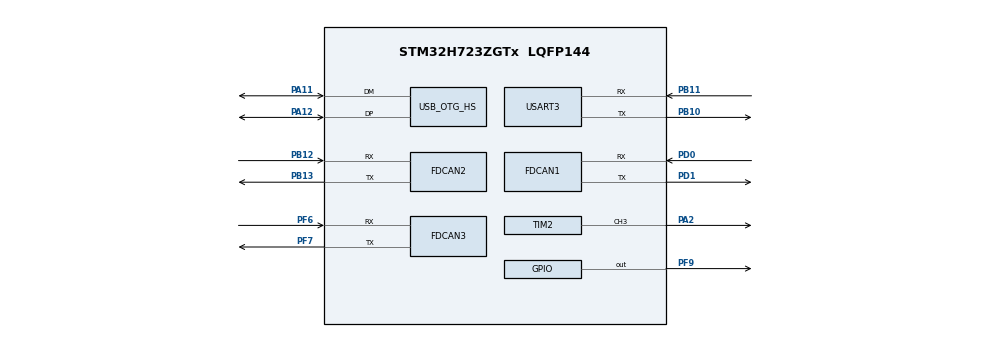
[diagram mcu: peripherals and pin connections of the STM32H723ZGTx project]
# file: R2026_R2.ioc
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CORTEX_M7.default_mode_Activation=1
Dma.Request0=USART3_RX
Dma.Request1=USART3_TX
Dma.USART3_RX.0.Direction=DMA_PERIPH_TO_MEMORY
Dma.USART3_RX.0.EventEnable=DISABLE
Dma.USART3_RX.0.FIFOMode=DMA_FIFOMODE_DISABLE
Dma.USART3_RX.0.Instance=DMA1_Stream0
Dma.USART3_RX.0.MemDataAlignment=DMA_MDATAALIGN_BYTE
Dma.USART3_RX.0.MemInc=DMA_MINC_ENABLE
Dma.USART3_RX.0.Mode=DMA_CIRCULAR
Dma.USART3_RX.0.PeriphDataAlignment=DMA_PDATAALIGN_BYTE
Dma.USART3_RX.0.PeriphInc=DMA_PINC_DISABLE
Dma.USART3_RX.0.Polarity=HAL_DMAMUX_REQ_GEN_RISING
Dma.USART3_RX.0.Priority=DMA_PRIORITY_LOW
Dma.USART3_RX.0.RequestNumber=1
Dma.USART3_RX.0.SignalID=NONE
Dma.USART3_RX.0.SyncEnable=DISABLE
Dma.USART3_RX.0.SyncPolarity=HAL_DMAMUX_SYNC_NO_EVENT
Dma.USART3_RX.0.SyncRequestNumber=1
Dma.USART3_RX.0.SyncSignalID=NONE
Dma.USART3_TX.1.Direction=DMA_MEMORY_TO_PERIPH
Dma.USART3_TX.1.EventEnable=DISABLE
Dma.USART3_TX.1.FIFOMode=DMA_FIFOMODE_DISABLE
Dma.USART3_TX.1.Instance=DMA1_Stream1
Dma.USART3_TX.1.MemDataAlignment=DMA_MDATAALIGN_BYTE
Dma.USART3_TX.1.MemInc=DMA_MINC_ENABLE
Dma.USART3_TX.1.Mode=DMA_NORMAL
Dma.USART3_TX.1.PeriphDataAlignment=DMA_PDATAALIGN_BYTE
Dma.USART3_TX.1.PeriphInc=DMA_PINC_DISABLE
Dma.USART3_TX.1.Polarity=HAL_DMAMUX_REQ_GEN_RISING
Dma.USART3_TX.1.Priority=DMA_PRIORITY_LOW
Dma.USART3_TX.1.RequestNumber=1
Dma.USART3_TX.1.SignalID=NONE
Dma.USART3_TX.1.SyncEnable=DISABLE
Dma.USART3_TX.1.SyncPolarity=HAL_DMAMUX_SYNC_NO_EVENT
Dma.USART3_TX.1.SyncRequestNumber=1
Dma.USART3_TX.1.SyncSignalID=NONE
FDCAN1.CalculateBaudRateNominal=1000000
FDCAN1.CalculateTimeBitNominal=1000
FDCAN1.CalculateTimeQuantumNominal=40.0
FDCAN1.DataSyncJumpWidth=2
FDCAN1.DataTimeSeg1=15
FDCAN1.DataTimeSeg2=9
FDCAN1.ExtFiltersNbr=2
FDCAN1.NominalPrescaler=1
FDCAN1.NominalSyncJumpWidth=2
FDCAN1.NominalTimeSeg1=15
FDCAN1.NominalTimeSeg2=9
FDCAN1.RxFifo0ElmtsNbr=8
FDCAN1.RxFifo1ElmtsNbr=8
FDCAN1.StdFiltersNbr=2
FDCAN1.TxBuffersNbr=29
FDCAN1.TxFifoQueueElmtsNbr=3
FDCAN2.CalculateBaudRateNominal=1000000
FDCAN2.CalculateTimeBitNominal=1000
FDCAN2.CalculateTimeQuantumNominal=40.0
FDCAN2.DataSyncJumpWidth=2
FDCAN2.DataTimeSeg1=15
FDCAN2.DataTimeSeg2=9
FDCAN2.ExtFiltersNbr=2
FDCAN2.MessageRAMOffset=0x400
FDCAN2.NominalPrescaler=1
FDCAN2.NominalSyncJumpWidth=2
FDCAN2.NominalTimeSeg1=15
FDCAN2.NominalTimeSeg2=9
FDCAN2.RxFifo0ElmtsNbr=8
FDCAN2.RxFifo1ElmtsNbr=8
FDCAN2.StdFiltersNbr=2
FDCAN2.TxBuffersNbr=29
FDCAN2.TxFifoQueueElmtsNbr=3
FDCAN3.CalculateBaudRateNominal=1000000
FDCAN3.CalculateTimeBitNominal=1000
FDCAN3.CalculateTimeQuantumNominal=40.0
FDCAN3.DataSyncJumpWidth=2
FDCAN3.DataTimeSeg1=15
FDCAN3.DataTimeSeg2=9
FDCAN3.ExtFiltersNbr=2
FDCAN3.MessageRAMOffset=0x800
FDCAN3.NominalPrescaler=1
FDCAN3.NominalSyncJumpWidth=2
FDCAN3.NominalTimeSeg1=15
FDCAN3.NominalTimeSeg2=9
FDCAN3.RxFifo0ElmtsNbr=8
FDCAN3.RxFifo1ElmtsNbr=8
FDCAN3.StdFiltersNbr=2
FDCAN3.TxBuffersNbr=29
FDCAN3.TxFifoQueueElmtsNbr=3
FREERTOS.Tasks01=defaultTask,24,128,StartDefaultTask,Default,NULL,Dynamic,NULL,NULL
FREERTOS.configENABLE_FPU=1
Mcu.Family=STM32H7
Mcu.Name=STM32H723ZGTx
Mcu.Package=LQFP144
NVIC.DMA1_Stream0_IRQn=true\:5\:0\:false\:false\:true\:true\:false\:true\:true
NVIC.DMA1_Stream1_IRQn=true\:5\:0\:false\:false\:true\:true\:false\:true\:true
NVIC.FDCAN1_IT0_IRQn=true\:5\:0\:false\:false\:true\:true\:true\:true\:true
NVIC.FDCAN1_IT1_IRQn=true\:5\:0\:false\:false\:true\:true\:true\:true\:true
NVIC.FDCAN2_IT0_IRQn=true\:5\:0\:false\:false\:true\:true\:true\:true\:true
NVIC.FDCAN2_IT1_IRQn=true\:5\:0\:false\:false\:true\:true\:true\:true\:true
NVIC.FDCAN3_IT0_IRQn=true\:5\:0\:false\:false\:true\:true\:true\:true\:true
NVIC.FDCAN3_IT1_IRQn=true\:5\:0\:false\:false\:true\:true\:true\:true\:true
NVIC.OTG_HS_IRQn=true\:5\:0\:false\:false\:true\:true\:false\:true\:true
NVIC.PriorityGroup=NVIC_PRIORITYGROUP_4
NVIC.TIM6_DAC_IRQn=true\:15\:0\:false\:false\:true\:false\:false\:true\:true
NVIC.TimeBase=TIM6_DAC_IRQn
NVIC.TimeBaseIP=TIM6
NVIC.USART3_IRQn=true\:5\:0\:false\:false\:true\:true\:true\:true\:true
PA11.Mode=Device_Only_FS
PA11.Signal=USB_OTG_HS_DM
PA12.Mode=Device_Only_FS
PA12.Signal=USB_OTG_HS_DP
PA2.Signal=S_TIM2_CH3
PB10.Mode=Asynchronous
PB10.Signal=USART3_TX
PB11.Mode=Asynchronous
PB11.Signal=USART3_RX
PB12.Mode=FDCAN_Activate
PB12.Signal=FDCAN2_RX
PB13.Mode=FDCAN_Activate
PB13.Signal=FDCAN2_TX
PD0.Mode=FDCAN_Activate
PD0.Signal=FDCAN1_RX
PD1.Mode=FDCAN_Activate
PD1.Signal=FDCAN1_TX
PF6.Mode=FDCAN_Activate
PF6.Signal=FDCAN3_RX
PF7.Mode=FDCAN_Activate
PF7.Signal=FDCAN3_TX
PF9.Signal=GPIO_Output
PH0-OSC_IN.Mode=HSE-External-Oscillator
PH0-OSC_IN.Signal=RCC_OSC_IN
PH1-OSC_OUT.Mode=HSE-External-Oscillator
PH1-OSC_OUT.Signal=RCC_OSC_OUT
ProjectManager.HeapSize=0x200
ProjectManager.StackSize=0x400
ProjectManager.TargetToolchain=CMake
RCC.ADCFreq_Value=50390625
RCC.APB1Freq_Value=137500000
RCC.APB2Freq_Value=137500000
RCC.APB3Freq_Value=137500000
RCC.APB4Freq_Value=137500000
RCC.CortexFreq_Value=275000000
RCC.D1PPRE=RCC_APB3_DIV2
RCC.D2PPRE1=RCC_APB1_DIV2
RCC.D2PPRE2=RCC_APB2_DIV2
RCC.D3PPRE=RCC_APB4_DIV2
RCC.DIVM1=2
RCC.DIVN1=22
RCC.DIVP1=1
RCC.FDCANCLockSelection=RCC_FDCANCLKSOURCE_HSE
RCC.HCLKFreq_Value=275000000
RCC.PLL2FRACN=0
RCC.PLL3FRACN=0
RCC.PLLFRACN=0
RCC.PLLSourceVirtual=RCC_PLLSOURCE_HSE
RCC.SYSCLKFreq_VALUE=275000000
RCC.SYSCLKSource=RCC_SYSCLKSOURCE_PLLCLK
RCC.USBCLockSelection=RCC_USBCLKSOURCE_HSI48
RCC.USBFreq_Value=48000000
SH.S_TIM2_CH3.0=TIM2_CH3,PWM Generation3 CH3
TIM2.Channel-PWM\ Generation3\ CH3=TIM_CHANNEL_3
TIM2.Period=100-1
USART3.VirtualMode-Asynchronous=VM_ASYNC
USB_DEVICE.CLASS_NAME_HS=CDC
USB_DEVICE.VirtualMode=Cdc
USB_DEVICE.VirtualModeHS=Cdc_HS
USB_OTG_HS.VirtualMode-Device_Only_FS=Device_Only_FS
VP_FREERTOS_VS_CMSIS_V2.Mode=CMSIS_V2
VP_MEMORYMAP_VS_MEMORYMAP.Mode=CurAppReg
VP_SYS_VS_tim6.Mode=TIM6
VP_USB_DEVICE_VS_USB_DEVICE_CDC_HS.Mode=CDC_HS
board=custom

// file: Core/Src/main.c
/* USER CODE BEGIN Header */
/**
 ******************************************************************************
 * @file           : main.c
 * @brief          : Main program body
 ******************************************************************************
 * @attention
 *
 * Copyright (c) 2026 STMicroelectronics.
 * All rights reserved.
 *
 * This software is licensed under terms that can be found in the LICENSE file
 * in the root directory of this software component.
 * If no LICENSE file comes with this software, it is provided AS-IS.
 *
 ******************************************************************************
 */
/* USER CODE END Header */
#include "main.h"
#include "FreeRTOS.h"
#include "cmsis_os2.h"
#include "dma.h"
#include "fdcan.h"
#include "gpio.h"
#include "tim.h"
#include "usart.h"
#include "usb_device.h"

/* USER CODE BEGIN Includes */
#include "robot.h"
/* USER CODE END Includes */

void SystemClock_Config(void);
static void MPU_Config(void);
void MX_FREERTOS_Init(void);

int main(void) {

  /* MPU Configuration--------------------------------------------------------*/
  MPU_Config();

  /* MCU Configuration--------------------------------------------------------*/

  /* Reset of all peripherals, Initializes the Flash interface and the Systick.
   */
  HAL_Init();

  /* Configure the system clock */
  SystemClock_Config();

  /* Initialize all configured peripherals */
  MX_GPIO_Init();
  MX_DMA_Init();
  MX_FDCAN1_Init();
  MX_FDCAN2_Init();
  MX_FDCAN3_Init();
  MX_TIM2_Init();
  MX_USART3_UART_Init();
  /* USER CODE BEGIN 2 */
  Robot_Init();
  /* USER CODE END 2 */

  /* Init scheduler */
  osKernelInitialize(); /* Call init function for freertos objects (in
                           cmsis_os2.c) */
  MX_FREERTOS_Init();

  /* Start scheduler */
  osKernelStart();

  /* We should never get here as control is now taken by the scheduler */

  /* Infinite loop */
  while (1) {

  }
}

void SystemClock_Config(void) {
  RCC_OscInitTypeDef RCC_OscInitStruct = {0};
  RCC_ClkInitTypeDef RCC_ClkInitStruct = {0};

  /** Supply configuration update enable
   */
  HAL_PWREx_ConfigSupply(PWR_LDO_SUPPLY);

  /** Configure the main internal regulator output voltage
   */
  __HAL_PWR_VOLTAGESCALING_CONFIG(PWR_REGULATOR_VOLTAGE_SCALE0);

  while (!__HAL_PWR_GET_FLAG(PWR_FLAG_VOSRDY)) {
  }

  /** Initializes the RCC Oscillators according to the specified parameters
   * in the RCC_OscInitTypeDef structure.
   */
  RCC_OscInitStruct.OscillatorType =
      RCC_OSCILLATORTYPE_HSI48 | RCC_OSCILLATORTYPE_HSE;
  RCC_OscInitStruct.HSEState = RCC_HSE_ON;
  RCC_OscInitStruct.HSI48State = RCC_HSI48_ON;
  RCC_OscInitStruct.PLL.PLLState = RCC_PLL_ON;
  RCC_OscInitStruct.PLL.PLLSource = RCC_PLLSOURCE_HSE;
  RCC_OscInitStruct.PLL.PLLM = 2;
  RCC_OscInitStruct.PLL.PLLN = 22;
  RCC_OscInitStruct.PLL.PLLP = 1;
  RCC_OscInitStruct.PLL.PLLQ = 2;
  RCC_OscInitStruct.PLL.PLLR = 2;
  RCC_OscInitStruct.PLL.PLLRGE = RCC_PLL1VCIRANGE_3;
  RCC_OscInitStruct.PLL.PLLVCOSEL = RCC_PLL1VCOWIDE;
  RCC_OscInitStruct.PLL.PLLFRACN = 0;
  if (HAL_RCC_OscConfig(&RCC_OscInitStruct) != HAL_OK) {
    Error_Handler();
  }

  /** Initializes the CPU, AHB and APB buses clocks
   */
  RCC_ClkInitStruct.ClockType = RCC_CLOCKTYPE_HCLK | RCC_CLOCKTYPE_SYSCLK |
                                RCC_CLOCKTYPE_PCLK1 | RCC_CLOCKTYPE_PCLK2 |
                                RCC_CLOCKTYPE_D3PCLK1 | RCC_CLOCKTYPE_D1PCLK1;
  RCC_ClkInitStruct.SYSCLKSource = RCC_SYSCLKSOURCE_PLLCLK;
  RCC_ClkInitStruct.SYSCLKDivider = RCC_SYSCLK_DIV1;
  RCC_ClkInitStruct.AHBCLKDivider = RCC_HCLK_DIV1;
  RCC_ClkInitStruct.APB3CLKDivider = RCC_APB3_DIV2;
  RCC_ClkInitStruct.APB1CLKDivider = RCC_APB1_DIV2;
  RCC_ClkInitStruct.APB2CLKDivider = RCC_APB2_DIV2;
  RCC_ClkInitStruct.APB4CLKDivider = RCC_APB4_DIV2;

  if (HAL_RCC_ClockConfig(&RCC_ClkInitStruct, FLASH_LATENCY_3) != HAL_OK) {
    Error_Handler();
  }
}

/* MPU Configuration */

void MPU_Config(void) {
  MPU_Region_InitTypeDef MPU_InitStruct = {0};

  /* Disables the MPU */
  HAL_MPU_Disable();

  /** Initializes and configures the Region and the memory to be protected
   */
  MPU_InitStruct.Enable = MPU_REGION_ENABLE;
  MPU_InitStruct.Number = MPU_REGION_NUMBER0;
  MPU_InitStruct.BaseAddress = 0x0;
  MPU_InitStruct.Size = MPU_REGION_SIZE_4GB;
  MPU_InitStruct.SubRegionDisable = 0x87;
  MPU_InitStruct.TypeExtField = MPU_TEX_LEVEL0;
  MPU_InitStruct.AccessPermission = MPU_REGION_NO_ACCESS;
  MPU_InitStruct.DisableExec = MPU_INSTRUCTION_ACCESS_DISABLE;
  MPU_InitStruct.IsShareable = MPU_ACCESS_SHAREABLE;
  MPU_InitStruct.IsCacheable = MPU_ACCESS_NOT_CACHEABLE;
  MPU_InitStruct.IsBufferable = MPU_ACCESS_NOT_BUFFERABLE;

  HAL_MPU_ConfigRegion(&MPU_InitStruct);
  /* Enables the MPU */
  HAL_MPU_Enable(MPU_PRIVILEGED_DEFAULT);
}

void HAL_TIM_PeriodElapsedCallback(TIM_HandleTypeDef *htim) {
  if (htim->Instance == TIM6) {
    HAL_IncTick();
  }
}

void Error_Handler(void) {
  __disable_irq();
  while (1) {
  }
}
#ifdef USE_FULL_ASSERT
/**
 * @brief  Reports the name of the source file and the source line number
 *         where the assert_param error has occurred.
 * @param  file: pointer to the source file name
 * @param  line: assert_param error line source number
 * @retval None
 */
void assert_failed(uint8_t *file, uint32_t line) {
  /* USER CODE BEGIN 6 */
  /* User can add his own implementation to report the file name and line
     number, ex: printf("Wrong parameters value: file %s on line %d\r\n", file,
     line) */
  /* USER CODE END 6 */
}
#endif /* USE_FULL_ASSERT */
